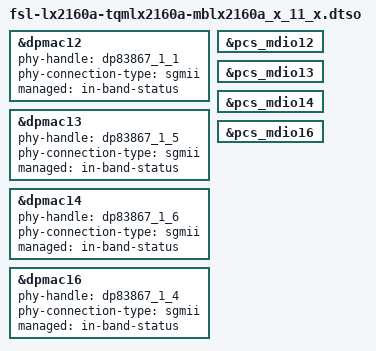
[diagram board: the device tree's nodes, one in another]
// SPDX-License-Identifier: GPL-2.0-or-later OR MIT
/*
 * Copyright (c) 2020-2023 TQ-Systems GmbH <linux@ew.tq-group.com>,
 * D-82229 Seefeld, Germany.
 * Author: Gregor Herburger
 */

/dts-v1/;
/plugin/;

&dpmac12 {
	phy-handle = <&dp83867_1_1>;
	phy-connection-type = "sgmii";
	managed = "in-band-status";
};

&dpmac13 {
	phy-handle = <&dp83867_1_5>;
	phy-connection-type = "sgmii";
	managed = "in-band-status";
};

&dpmac14 {
	phy-handle = <&dp83867_1_6>;
	phy-connection-type = "sgmii";
	managed = "in-band-status";
};

&dpmac16 {
	phy-handle = <&dp83867_1_4>;
	phy-connection-type = "sgmii";
	managed = "in-band-status";
};

&pcs_mdio12 {
	status = "okay";
};

&pcs_mdio13 {
	status = "okay";
};

&pcs_mdio14 {
	status = "okay";
};

&pcs_mdio16 {
	status = "okay";
};
